# haltium_sysctrl register map
Vendor: Nordic Semiconductor; Series: nRFHaltium; File version: 1
Registers are 32-bit, read-write, reset 0x0 unless marked. A register's access mark holds for its fields unless they carry their own. Offsets are from the block's base; [hi:lo] are bit positions; lines under a group give offsets from that group; 'fields as' and 'values as' point back to an identical list.

## VDETVS0V8_S — VDETVS0V8
Base 0x5F973000
0x00 TASKS_PWRUP wo — Power up voltage detector
  [0] TASKS_PWRUP
    1=Trigger task
0x04 TASKS_PWRDOWN wo — Power down voltage detector
  [0] TASKS_PWRDOWN
    1=Trigger task
0x08 TASKS_STARTPWRGOOD wo — Start power good detection
  [0] TASKS_STARTPWRGOOD
    1=Trigger task
0x0C TASKS_CANCELPWRGOOD wo — Cancel power good detection
  [0] TASKS_CANCELPWRGOOD
    1=Trigger task
0x100 EVENTS_READY — Power up done
  [0] EVENTS_READY
    0=NotGenerated (Event not generated); 1=Generated (Event generated)
0x104 EVENTS_PWRGOOD — Power good detector detected voltage above threshold level
  [0] EVENTS_PWRGOOD
    values as EVENTS_READY.EVENTS_READY
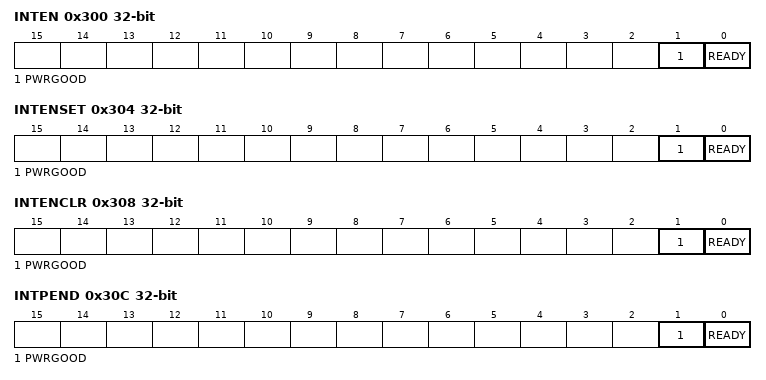
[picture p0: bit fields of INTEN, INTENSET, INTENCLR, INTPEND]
0x300 INTEN — Enable or disable interrupt
  [1] PWRGOOD — Enable or disable interrupt for event PWRGOOD
    0=Disabled; 1=Enabled
  [0] READY — Enable or disable interrupt for event READY
    0=Disabled; 1=Enabled
0x304 INTENSET — Enable interrupt
  [1] PWRGOOD — Write '1' to enable interrupt for event PWRGOOD
    on read: 0=Disabled (Read: Disabled); 1=Enabled (Read: Enabled) | on write: 1=Set (Enable)
  [0] READY — Write '1' to enable interrupt for event READY
    values as PWRGOOD
0x308 INTENCLR — Disable interrupt
  [1] PWRGOOD — Write '1' to disable interrupt for event PWRGOOD
    on read: 0=Disabled (Read: Disabled); 1=Enabled (Read: Enabled) | on write: 1=Clear (Disable)
  [0] READY — Write '1' to disable interrupt for event READY
    values as PWRGOOD
0x30C INTPEND ro — Pending interrupts
  [1] PWRGOOD — Read pending status of interrupt for event PWRGOOD
    on read: 0=NotPending (Read: Not pending); 1=Pending (Read: Pending)
  [0] READY — Read pending status of interrupt for event READY
    values as PWRGOOD
0x400 STATUS ro — Voltage detector status
  [1:0] MODE — Current voltage detector mode
    0=High power mode; 1=Low power mode; 2=Ultra-low power refresh mode
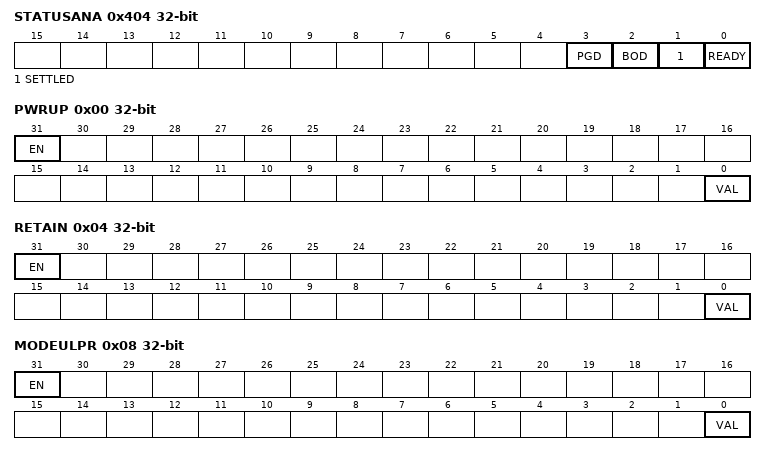
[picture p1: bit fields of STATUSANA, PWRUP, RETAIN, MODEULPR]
0x404 STATUSANA ro — Status of analog module output signals
  [3] PGD — Current value of the PGD signal from the analog module
  [2] BOD — Current value of the BOD signal from the analog module
  [1] SETTLED — Current value of the SETTLED signal from the analog module
  [0] READY — Current value of the READY signal from the analog module
0x410 CONFIG group — Unspecified
  0x00 CFG — Voltage detector configuration
    [1:0] BROWNOUTHYST — Brown out detector hysteresis voltage value
      0=Val0V0250 (Hysteresis voltage is 25mV); 1=Val0V0500 (Hysteresis voltage is 50mV); 2=Val0V0125 (Hysteresis voltage is 12.5mV); 3=Val0V0167 (Hysteresis voltage is 16.7mV)
  0x04 BROWNOUTLVL reset 0x2F — Brown out detector threshold voltage level
    [5:0] VAL — Threshold voltage value.
  0x08 PWRGOODLVL reset 0x2F — Power good detector threshold voltage level
    [5:0] VAL — Threshold voltage value.
0x440 TRIM group — Unspecified
  0x00 BROWNOUT — Brown out detector trimming
    [2:0] VAL — Threshold voltage deviation value.
  0x04 PWRGOOD — Power good detector trimming
    [2:0] VAL — Threshold voltage trimming deviation value.
0x480 MIRROR reset 0x1 — Enable LOCK for mirrored registers
  [0] LOCK — Lock for mirrored registers
    0=Disabled (Lock disabled); 1=Enabled (Lock enabled)
0x484 MODE — Voltage detector mode
  [2:0] MODE
    0=Automatically handled by the MMI; 1=High power mode; 2=Low power mode; 3=Ultra-low power refresh mode
0x500 OVERRIDE group — Unspecified
  0x00 PWRUP — Override the PWRUP signal to the analog module
    [31] EN — Enable the override
      0=Disabled (Override is disabled); 1=Enabled (Override is enabled)
    [0] VAL — Override value for the signal
  0x04 RETAIN — Override the RETAIN signal to the analog module
    fields as OVERRIDE.PWRUP
  0x08 MODEULPR — Override the MODE_ULPR signal to the analog module
    fields as OVERRIDE.PWRUP
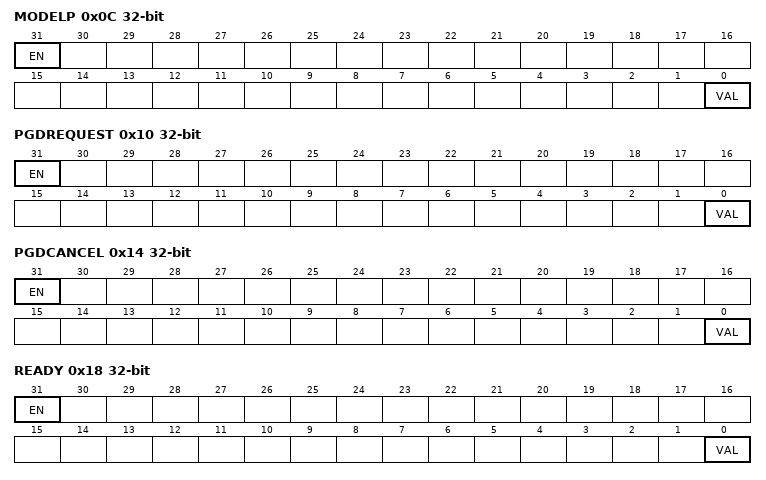
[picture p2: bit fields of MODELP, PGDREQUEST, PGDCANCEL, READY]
  0x0C MODELP — Override the MODE_LP signal to the analog module
    fields as OVERRIDE.PWRUP
  0x10 PGDREQUEST — Override the PGD_REQUEST signal to the analog module
    fields as OVERRIDE.PWRUP
  0x14 PGDCANCEL — Override the PGD_CANCEL signal to the analog module
    fields as OVERRIDE.PWRUP
  0x18 READY — Override the READY signal from the analog module
    [31] EN — Enable the override
      values as OVERRIDE.PWRUP.EN
    [0] VAL — Current value of the signal
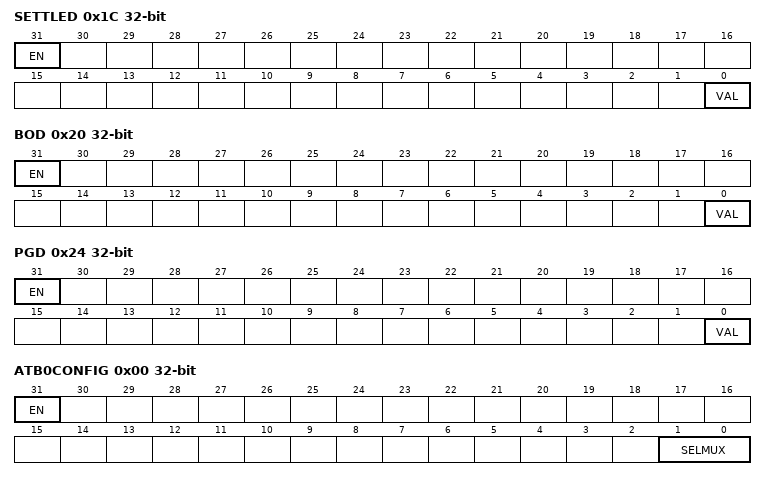
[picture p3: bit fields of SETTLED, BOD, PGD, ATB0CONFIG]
  0x1C SETTLED — Override the SETTLED signal from the analog module
    fields as OVERRIDE.READY
  0x20 BOD — Override the BOD signal from the analog module
    fields as OVERRIDE.READY
  0x24 PGD — Override the PGD signal from the analog module
    fields as OVERRIDE.READY
0x600 DFT group — Unspecified
  0x00 ATB0CONFIG — Analog Test Bus 0 (ATB0) configuration
    [31] EN — Enable the analog test bus
      0=Disabled (Analog test bus is disabled); 1=Enabled (Analog test bus is enabled)
    [1:0] SELMUX — Select multiplexer for ATB0
      0=None selected; 1=ConnectIDBG2U (Connect IDBG_1U to ATB0); 2=Connect VSS to ATB0; 3=ConnectSenseVoltage (Use ATB0 as sense voltage instead of VDD_SENSE_0V8)
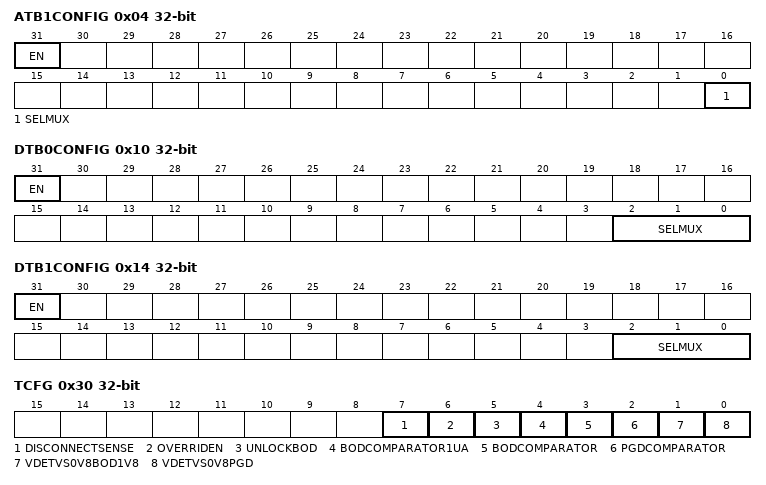
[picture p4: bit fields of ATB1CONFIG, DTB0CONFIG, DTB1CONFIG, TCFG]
  0x04 ATB1CONFIG — Analog Test Bus 1 (ATB1) configuration
    [31] EN — Enable the analog test bus
      values as DFT.ATB0CONFIG.EN
    [0] SELMUX — Select multiplexer for ATB1
      0=None selected; 1=Connect VREF_BOD to ATB1
  0x10 DTB0CONFIG — Digital Test Bus 0 (DTB0) configuration
    [31] EN — Enable the digital test bus
      0=Disabled (Digital test bus is disabled); 1=Enabled (Digital test bus is enabled)
    [2:0] SELMUX — Select multiplexer for DTB0
      0=None selected; 1=SETTLED_VDETVS0V8_VS_0V8; 2=PGDCompOutput (PGD comparator output); 3=PGDCompOutputPost (PGD comparator output after the handshake logic.); 4=PWRUPPGDSW1V8; 6=BODLockAckSW1V8
  0x14 DTB1CONFIG — Digital Test Bus 1 (DTB1) configuration
    [31] EN — Enable the digital test bus
      values as DFT.DTB0CONFIG.EN
    [2:0] SELMUX — Select multiplexer for DTB1
      0=None selected; 1=READY_VDETVS0V8_VS_0V8; 2=BODCompOutput (BOD comparator output); 3=BODCompOutputPost (BOD comparator output after the handshake logic.); 4=PWRUPBODSW1V8; 5=PWRUPBODBIASSW1V8; 6=BODLockAckSW1V8; 7=ReadtBODSW1V8 (READY_BOD_SW_1V8)
  0x1C DTB3CONFIG — Digital Test Bus 3 (DTB3) configuration
    [30] PWRUPDELTEST — Enable the PWRUP delay test circuit
      0=Disabled (PWRUP delay test circuit is disabled); 1=Enabled (PWRUP delay test circuit is enabled)
  0x30 TCFG — Test mode configuration
    [7] DISCONNECTSENSE — Disconnect the sense line of the comparator and short-circuit both inputs of the comparator to vref.
    [6] OVERRIDEN — Override of the internal logic to change the power-up and power-down of internal blocks independently.
    [5] UNLOCKBOD — Unlock the BOD deglitch logic when TCFG.OVERRIDEN is one. No effect when bit TCFG.OVERRIDEN is 0.
    [4] BODCOMPARATOR1UA — If bit TCFG.OVERRIDEN is one, this bit will directly control power-up or power-down the BOD comparator 1uA bias.
    [3] BODCOMPARATOR — If bit TCFG.OVERRIDEN is one, this bit will directly control power-up or power-down the BOD comparator.
    [2] PGDCOMPARATOR — If bit TCFG.OVERRIDEN is one, this bit will directly control the internal power-up or power-down the PGD comparator.
    [1] VDETVS0V8BOD1V8 — Override VDETVS0V8_BOD_VS_0V8 and VDETVS0V8_BOD_VS_1V8 to 0
      0=Disabled (Override disabled); 1=Enabled (Override enabled)
    [0] VDETVS0V8PGD — Override VDETVS0V8_PGD_VS_0V8
      0=Disabled (Override disabled); 1=Enabled (Override enabled)
